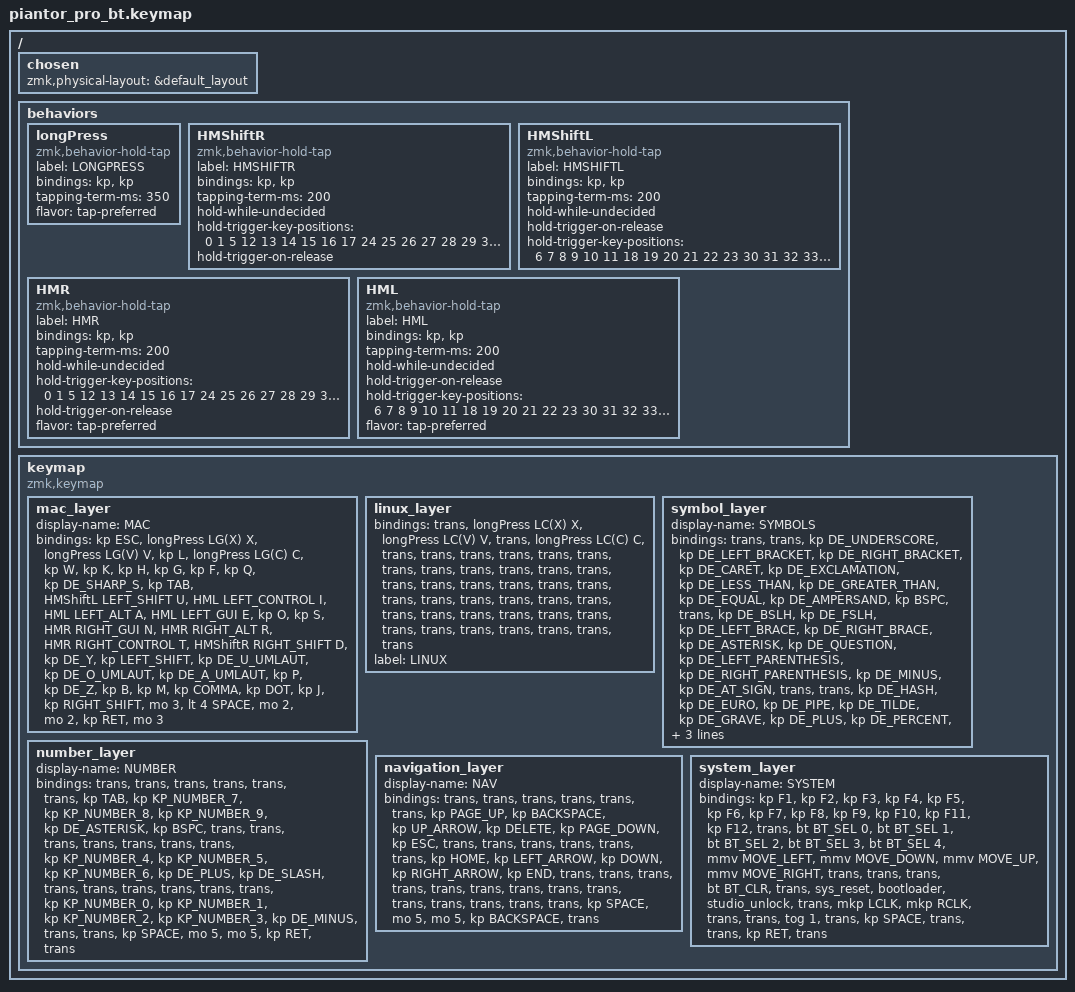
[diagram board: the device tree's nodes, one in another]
/*
 * Copyright (c) 2020 The ZMK Contributors
 *
 * SPDX-License-Identifier: MIT
 */

#include "keys_de.h"
#include <behaviors.dtsi>
#include <dt-bindings/zmk/bt.h>
#include <dt-bindings/zmk/keys.h>
#include <dt-bindings/zmk/pointing.h>

/ {
    chosen { zmk,physical-layout = &default_layout; };
};

/ {
    behaviors {
        longPress: longPress {
            compatible = "zmk,behavior-hold-tap";
            label = "LONGPRESS";
            bindings = <&kp>, <&kp>;

            #binding-cells = <2>;
            tapping-term-ms = <350>;
            flavor = "tap-preferred";
        };

        HMShiftR: HMShiftR {
            compatible = "zmk,behavior-hold-tap";
            label = "HMSHIFTR";
            bindings = <&kp>, <&kp>;

            #binding-cells = <2>;
            tapping-term-ms = <200>;
            hold-while-undecided;
            hold-trigger-key-positions = <0 1 5 12 13 14 15 16 17 24 25 26 27 28 29 36 37 38 2 3 4>;
            hold-trigger-on-release;
        };

        HMShiftL: HMShiftL {
            compatible = "zmk,behavior-hold-tap";
            label = "HMSHIFTL";
            bindings = <&kp>, <&kp>;

            #binding-cells = <2>;
            tapping-term-ms = <200>;
            hold-while-undecided;
            hold-trigger-on-release;
            hold-trigger-key-positions = <6 7 8 9 10 11 18 19 20 21 22 23 30 31 32 33 34 35 39 40 41>;
        };

        HMR: HMR {
            compatible = "zmk,behavior-hold-tap";
            label = "HMR";
            bindings = <&kp>, <&kp>;

            #binding-cells = <2>;
            tapping-term-ms = <200>;
            hold-while-undecided;
            hold-trigger-key-positions = <0 1 5 12 13 14 15 16 17 24 25 26 27 28 29 36 37 38 2 3 4>;
            hold-trigger-on-release;
            flavor = "tap-preferred";
        };

        HML: HML {
            compatible = "zmk,behavior-hold-tap";
            label = "HML";
            bindings = <&kp>, <&kp>;

            #binding-cells = <2>;
            tapping-term-ms = <200>;
            hold-while-undecided;
            hold-trigger-on-release;
            hold-trigger-key-positions = <6 7 8 9 10 11 18 19 20 21 22 23 30 31 32 33 34 35 39 40 41>;
            flavor = "tap-preferred";
        };
    };

    keymap {
        compatible = "zmk,keymap";

        mac_layer {
            display-name = "MAC";

            // --------------------------------------------------------------------------------
            // |  TAB |  x  |  v  |  l  |  c  |  w  |  k  |  h   |  g  |  f  |  q  |  ß   |
            // | CTRL |  u  |  i  |  a  |  e  |  o  |  s  |  n   |  r  |  t  |  d  |  y   |
            // | SHFT |  ü  |  ö  |  ä  |  p  |  z  |  b  |  m   |  ,  |  .  |  j  | SHFT |
            //                    | GUI | SPC | LWR | RSE | ENT  | ALT |

            bindings = <
&kp ESC  &longPress LG(X) X  &longPress LG(V) V  &kp L  &longPress LG(C) C  &kp W  &kp K  &kp H  &kp G  &kp F  &kp Q  &kp DE_SHARP_S  &kp TAB  &HMShiftL LEFT_SHIFT U  &HML LEFT_CONTROL I  &HML LEFT_ALT A  &HML LEFT_GUI E  &kp O  &kp S  &HMR RIGHT_GUI N  &HMR RIGHT_ALT R  &HMR RIGHT_CONTROL T  &HMShiftR RIGHT_SHIFT D  &kp DE_Y  &kp LEFT_SHIFT  &kp DE_U_UMLAUT  &kp DE_O_UMLAUT  &kp DE_A_UMLAUT  &kp P  &kp DE_Z  &kp B  &kp M  &kp COMMA  &kp DOT  &kp J  &kp RIGHT_SHIFT  &mo 3  &lt 4 SPACE  &mo 2  &mo 2  &kp RET  &mo 3
            >;
        };

        linux_layer {
            bindings = <
&trans  &longPress LC(X) X  &longPress LC(V) V  &trans  &longPress LC(C) C  &trans  &trans  &trans  &trans  &trans  &trans  &trans  &trans  &trans  &trans  &trans  &trans  &trans  &trans  &trans  &trans  &trans  &trans  &trans  &trans  &trans  &trans  &trans  &trans  &trans  &trans  &trans  &trans  &trans  &trans  &trans  &trans  &trans  &trans  &trans  &trans  &trans
            >;

            label = "LINUX";
        };

        symbol_layer {
            display-name = "SYMBOLS";

            // -----------------------------------------------------------------------------------------
            // |  TAB |  1  |  2  |  3  |  4  |  5    |  6  |  7  |  8  |  9  |  0  | BSPC |
            // | CTRL | BT1 | BT2 | BT3 | BT4 | BT5   | LFT | DWN |  UP | RGT |     |      |
            // | SHFT | BTCR| RGB | RST | BOOT| Unlock|     |     |     |     |     |      |
            //                    | GUI | SPC |       |     | ENT | ALT |

            bindings = <
&trans  &trans  &kp DE_UNDERSCORE  &kp DE_LEFT_BRACKET  &kp DE_RIGHT_BRACKET  &kp DE_CARET  &kp DE_EXCLAMATION  &kp DE_LESS_THAN  &kp DE_GREATER_THAN  &kp DE_EQUAL  &kp DE_AMPERSAND  &kp BSPC  &trans  &kp DE_BSLH  &kp DE_FSLH  &kp DE_LEFT_BRACE  &kp DE_RIGHT_BRACE  &kp DE_ASTERISK  &kp DE_QUESTION  &kp DE_LEFT_PARENTHESIS  &kp DE_RIGHT_PARENTHESIS  &kp DE_MINUS  &kp DE_AT_SIGN  &trans  &trans  &kp DE_HASH  &kp DE_EURO  &kp DE_PIPE  &kp DE_TILDE  &kp DE_GRAVE  &kp DE_PLUS  &kp DE_PERCENT  &kp DE_DOUBLE_QUOTES  &kp DE_SQT  &trans  &trans  &mo 5  &kp SPACE  &trans  &trans  &kp RET  &mo 5
            >;
        };

        number_layer {
            display-name = "NUMBER";

            // -----------------------------------------------------------------------------------------
            // |  TAB |  !  |  @  |  #  |  $  |  %  |  ^  |  &  |  *  |  (  |  )  | BSPC |
            // | CTRL |     |     |     |     |     |  -  |  =  |  [  |  ]  |  \  |  `   |
            // | SHFT |     |     |     |     |     |  _  |  +  |  {  |  }  | "|" |  ~   |
            //                    | GUI | SPC |     |     | ENT | ALT |

            bindings = <
&trans  &trans  &trans  &trans  &trans  &trans  &kp TAB  &kp KP_NUMBER_7  &kp KP_NUMBER_8  &kp KP_NUMBER_9  &kp DE_ASTERISK  &kp BSPC  &trans  &trans  &trans  &trans  &trans  &trans  &trans  &kp KP_NUMBER_4  &kp KP_NUMBER_5  &kp KP_NUMBER_6  &kp DE_PLUS  &kp DE_SLASH  &trans  &trans  &trans  &trans  &trans  &trans  &kp KP_NUMBER_0  &kp KP_NUMBER_1  &kp KP_NUMBER_2  &kp KP_NUMBER_3  &kp DE_MINUS  &trans  &trans  &kp SPACE  &mo 5  &mo 5  &kp RET  &trans
            >;
        };

        navigation_layer {
            display-name = "NAV";
            bindings = <
&trans  &trans  &trans  &trans  &trans  &trans  &kp PAGE_UP  &kp BACKSPACE  &kp UP_ARROW  &kp DELETE  &kp PAGE_DOWN  &kp ESC  &trans  &trans  &trans  &trans  &trans  &trans  &kp HOME  &kp LEFT_ARROW  &kp DOWN  &kp RIGHT_ARROW  &kp END  &trans  &trans  &trans  &trans  &trans  &trans  &trans  &trans  &trans  &trans  &trans  &trans  &trans  &trans  &kp SPACE  &mo 5  &mo 5  &kp BACKSPACE  &trans
            >;
        };

        system_layer {
            display-name = "SYSTEM";
            bindings = <
&kp F1  &kp F2  &kp F3  &kp F4  &kp F5  &kp F6  &kp F7  &kp F8  &kp F9  &kp F10  &kp F11  &kp F12  &trans  &bt BT_SEL 0  &bt BT_SEL 1  &bt BT_SEL 2  &bt BT_SEL 3  &bt BT_SEL 4  &mmv MOVE_LEFT  &mmv MOVE_DOWN  &mmv MOVE_UP  &mmv MOVE_RIGHT  &trans  &trans  &trans  &bt BT_CLR  &trans  &sys_reset  &bootloader  &studio_unlock  &trans  &mkp LCLK  &mkp RCLK  &trans  &trans  &tog 1  &trans  &kp SPACE  &trans  &trans  &kp RET  &trans
            >;
        };
    };
};
